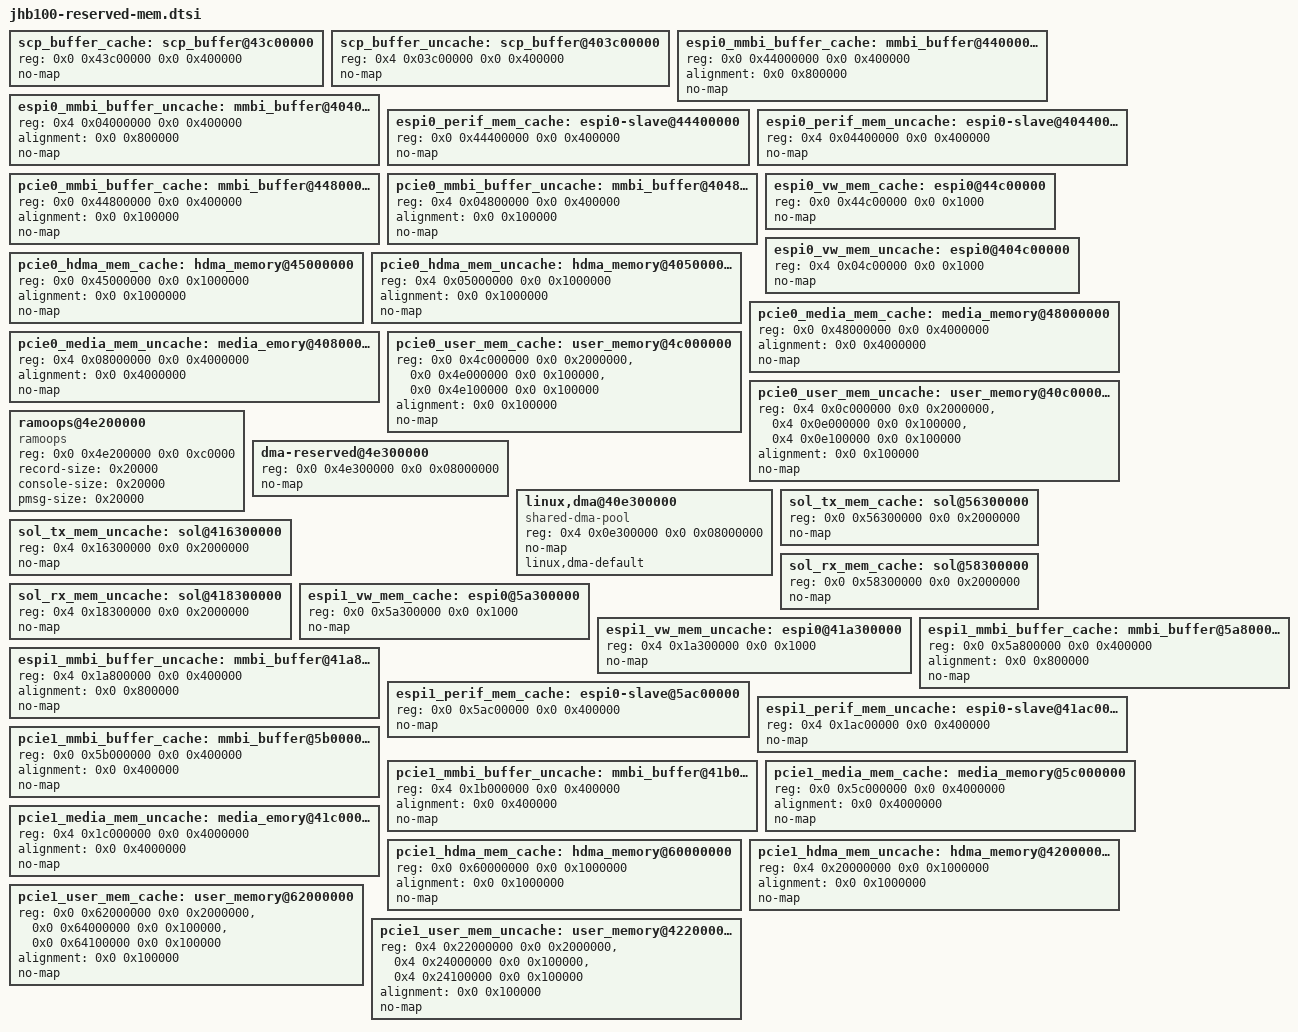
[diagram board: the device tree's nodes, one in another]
// SPDX-License-Identifier: GPL-2.0 OR MIT
/*
 * Copyright (c) 2025 StarFive Technology Co., Ltd.
 */

/* Add reserved memory region dedicated for SCP usage. */
scp_buffer_cache: scp_buffer@43c00000 {
    reg = <0x0 0x43c00000 0x0 0x400000>;
    no-map;
};

scp_buffer_uncache: scp_buffer@403c00000 {
    reg = <0x4 0x03c00000 0x0 0x400000>;
    no-map;
};

/*
 * eSPI & MMBI dma accesses uncached address.
 * Also need to reserve corresponding cache addresses,
 * so that kernel will not manage them.
 * There is only one adderss remap window for eSPI memory accessing,
 * so espi drive merges the reserved memory ranges
 * of MMBI over eSPI (1st 4MB) & eSPI memory cycle access(2nd 4MB).
 * The size of eSPI remap window must be power of 2.
 */
espi0_mmbi_buffer_cache: mmbi_buffer@44000000 {
	reg = <0x0 0x44000000 0x0 0x400000>;
	alignment = <0x0 0x800000>;
	no-map;
};

espi0_mmbi_buffer_uncache: mmbi_buffer@404000000 {
	reg = <0x4 0x04000000 0x0 0x400000>;
	alignment = <0x0 0x800000>;
	no-map;
};

espi0_perif_mem_cache: espi0-slave@44400000 {
	reg = <0x0 0x44400000 0x0 0x400000>;
	no-map;
};

espi0_perif_mem_uncache: espi0-slave@404400000 {
	reg = <0x4 0x04400000 0x0 0x400000>;
	no-map;
};

pcie0_mmbi_buffer_cache: mmbi_buffer@44800000 {
	reg = <0x0 0x44800000 0x0 0x400000>;
	alignment = <0x0 0x100000>;
	no-map;
};

pcie0_mmbi_buffer_uncache: mmbi_buffer@404800000 {
	reg = <0x4 0x04800000 0x0 0x400000>;
	alignment = <0x0 0x100000>;
	no-map;
};

espi0_vw_mem_cache: espi0@44c00000 {
	reg = <0x0 0x44c00000 0x0 0x1000>;
	no-map;
};

espi0_vw_mem_uncache: espi0@404c00000 {
	reg = <0x4 0x04c00000 0x0 0x1000>;
	no-map;
};

pcie0_hdma_mem_cache: hdma_memory@45000000 {
	reg = <0x0 0x45000000 0x0 0x1000000>;
	alignment = <0x0 0x1000000>;
	no-map;
};

pcie0_hdma_mem_uncache: hdma_memory@405000000 {
	reg = <0x4 0x05000000 0x0 0x1000000>;
	alignment = <0x0 0x1000000>;
	no-map;
};

pcie0_media_mem_cache: media_memory@48000000 {
	reg = <0x0 0x48000000 0x0 0x4000000>;
	alignment = <0x0 0x4000000>;
	no-map;
};

pcie0_media_mem_uncache: media_emory@408000000 {
	reg = <0x4 0x08000000 0x0 0x4000000>;
	alignment = <0x0 0x4000000>;
	no-map;
};

/*
 * As the ATU configuration required the dest_addr to keep align
 * with its size, the first reg below required to be aligned with
 * 0x2000000 too.
 */
pcie0_user_mem_cache: user_memory@4c000000 {
	reg = <0x0 0x4c000000 0x0 0x2000000>,
		<0x0 0x4e000000 0x0 0x100000>,
		<0x0 0x4e100000 0x0 0x100000>;
	alignment = <0x0 0x100000>;
	no-map;
};

pcie0_user_mem_uncache: user_memory@40c000000 {
	reg = <0x4 0x0c000000 0x0 0x2000000>,
		<0x4 0x0e000000 0x0 0x100000>,
		<0x4 0x0e100000 0x0 0x100000>;
	alignment = <0x0 0x100000>;
	no-map;
};

ramoops@4e200000 {
	compatible = "ramoops";
	reg = <0x0 0x4e200000 0x0 0xc0000>;
	record-size = <0x20000>;
	console-size = <0x20000>;
	pmsg-size = <0x20000>;
};

/* DMA global pool cached address */
dma-reserved@4e300000 {
	reg = <0x0 0x4e300000 0x0 0x08000000>;
	no-map;
};

/* DMA global pool uncached address (alias) */
linux,dma@40e300000 {
	compatible = "shared-dma-pool";
	reg = <0x4 0x0e300000 0x0 0x08000000>;
	no-map;
	linux,dma-default;
};

sol_tx_mem_cache: sol@56300000 {
	reg = <0x0 0x56300000 0x0 0x2000000>;
	no-map;
};

sol_tx_mem_uncache: sol@416300000 {
	reg = <0x4 0x16300000 0x0 0x2000000>;
	no-map;
};

sol_rx_mem_cache: sol@58300000 {
	reg = <0x0 0x58300000 0x0 0x2000000>;
	no-map;
};

sol_rx_mem_uncache: sol@418300000 {
	reg = <0x4 0x18300000 0x0 0x2000000>;
	no-map;
};

espi1_vw_mem_cache: espi0@5a300000 {
	reg = <0x0 0x5a300000 0x0 0x1000>;
	no-map;
};

espi1_vw_mem_uncache: espi0@41a300000 {
	reg = <0x4 0x1a300000 0x0 0x1000>;
	no-map;
};

espi1_mmbi_buffer_cache: mmbi_buffer@5a800000 {
	reg = <0x0 0x5a800000 0x0 0x400000>;
	alignment = <0x0 0x800000>;
	no-map;
};

espi1_mmbi_buffer_uncache: mmbi_buffer@41a800000 {
	reg = <0x4 0x1a800000 0x0 0x400000>;
	alignment = <0x0 0x800000>;
	no-map;
};

espi1_perif_mem_cache: espi0-slave@5ac00000 {
	reg = <0x0 0x5ac00000 0x0 0x400000>;
	no-map;
};

espi1_perif_mem_uncache: espi0-slave@41ac00000 {
	reg = <0x4 0x1ac00000 0x0 0x400000>;
	no-map;
};

pcie1_mmbi_buffer_cache: mmbi_buffer@5b000000 {
	reg = <0x0 0x5b000000 0x0 0x400000>;
	alignment = <0x0 0x400000>;
	no-map;
};

pcie1_mmbi_buffer_uncache: mmbi_buffer@41b000000 {
	reg = <0x4 0x1b000000 0x0 0x400000>;
	alignment = <0x0 0x400000>;
	no-map;
};

pcie1_media_mem_cache: media_memory@5c000000 {
	reg = <0x0 0x5c000000 0x0 0x4000000>;
	alignment = <0x0 0x4000000>;
	no-map;
};

pcie1_media_mem_uncache: media_emory@41c000000 {
	reg = <0x4 0x1c000000 0x0 0x4000000>;
	alignment = <0x0 0x4000000>;
	no-map;
};

pcie1_hdma_mem_cache: hdma_memory@60000000 {
	reg = <0x0 0x60000000 0x0 0x1000000>;
	alignment = <0x0 0x1000000>;
	no-map;
};

pcie1_hdma_mem_uncache: hdma_memory@420000000 {
	reg = <0x4 0x20000000 0x0 0x1000000>;
	alignment = <0x0 0x1000000>;
	no-map;
};

/*
 * As the ATU configuration required the dest_addr to keep align
 * with its size, the first reg below required to be aligned with
 * 0x2000000 too.
 */
pcie1_user_mem_cache: user_memory@62000000 {
	reg = <0x0 0x62000000 0x0 0x2000000>,
		<0x0 0x64000000 0x0 0x100000>,
		<0x0 0x64100000 0x0 0x100000>;
	alignment = <0x0 0x100000>;
	no-map;
};

pcie1_user_mem_uncache: user_memory@422000000 {
	reg = <0x4 0x22000000 0x0 0x2000000>,
		<0x4 0x24000000 0x0 0x100000>,
		<0x4 0x24100000 0x0 0x100000>;
	alignment = <0x0 0x100000>;
	no-map;
};
